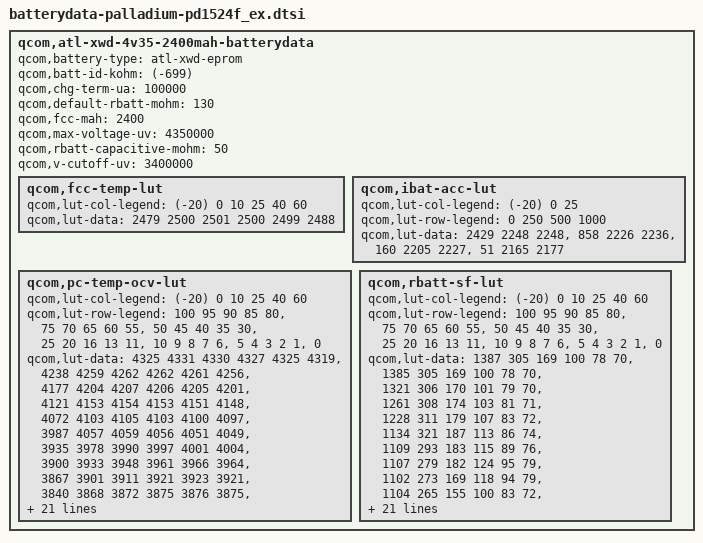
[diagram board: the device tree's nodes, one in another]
/* Copyright (c) 2013-2014, The Linux Foundation. All rights reserved.
 *
 * This program is free software; you can redistribute it and/or modify
 * it under the terms of the GNU General Public License version 2 and
 * only version 2 as published by the Free Software Foundation.
 *
 * This program is distributed in the hope that it will be useful,
 * but WITHOUT ANY WARRANTY; without even the implied warranty of
 * MERCHANTABILITY or FITNESS FOR A PARTICULAR PURPOSE.  See the
 * GNU General Public License for more details.
 */
qcom,atl-xwd-4v35-2400mah-batterydata {
	qcom,battery-type = "atl-xwd-eprom";
	qcom,batt-id-kohm = <(-699)>;
	qcom,chg-term-ua = <100000>;
	qcom,default-rbatt-mohm = <130>;
	qcom,fcc-mah = <2400>;
	qcom,max-voltage-uv = <4350000>;
	qcom,rbatt-capacitive-mohm = <50>;
	qcom,v-cutoff-uv = <3400000>;

	qcom,fcc-temp-lut {
		qcom,lut-col-legend = <(-20) 0 10 25 40 60>;
		qcom,lut-data = <2479 2500 2501 2500 2499 2488>;
	};

	qcom,ibat-acc-lut {
		qcom,lut-col-legend = <(-20) 0 25>;
		qcom,lut-row-legend = <0 250 500 1000>;
		qcom,lut-data = <2429 2248 2248>,
				<858 2226 2236>,
				<160 2205 2227>,
				<51 2165 2177>;
	};

	qcom,pc-temp-ocv-lut {
		qcom,lut-col-legend = <(-20) 0 10 25 40 60>;
		qcom,lut-row-legend = <100 95 90 85 80>,
					<75 70 65 60 55>,
					<50 45 40 35 30>,
					<25 20 16 13 11>,
					<10 9 8 7 6>,
					<5 4 3 2 1>,
					<0>;
		qcom,lut-data = <4325 4331 4330 4327 4325 4319>,
				<4238 4259 4262 4262 4261 4256>,
				<4177 4204 4207 4206 4205 4201>,
				<4121 4153 4154 4153 4151 4148>,
				<4072 4103 4105 4103 4100 4097>,
				<3987 4057 4059 4056 4051 4049>,
				<3935 3978 3990 3997 4001 4004>,
				<3900 3933 3948 3961 3966 3964>,
				<3867 3901 3911 3921 3923 3921>,
				<3840 3868 3872 3875 3876 3875>,
				<3820 3840 3843 3845 3845 3844>,
				<3804 3817 3821 3822 3822 3821>,
				<3790 3799 3802 3803 3803 3802>,
				<3777 3785 3787 3788 3788 3786>,
				<3764 3774 3775 3773 3769 3762>,
				<3750 3762 3762 3756 3748 3735>,
				<3733 3745 3746 3738 3729 3715>,
				<3717 3727 3725 3718 3708 3695>,
				<3704 3712 3707 3698 3688 3675>,
				<3692 3704 3700 3692 3683 3671>,
				<3684 3701 3698 3690 3682 3670>,
				<3674 3698 3695 3689 3680 3668>,
				<3661 3693 3693 3687 3678 3665>,
				<3647 3686 3688 3682 3673 3657>,
				<3626 3670 3674 3667 3655 3635>,
				<3593 3639 3641 3631 3618 3597>,
				<3551 3592 3595 3582 3568 3546>,
				<3492 3531 3535 3521 3505 3481>,
				<3405 3448 3439 3439 3422 3392>,
				<3258 3288 3291 3284 3298 3257>,
				<3000 3000 3000 3000 3000 3000>;
	};

	qcom,rbatt-sf-lut {
		qcom,lut-col-legend = <(-20) 0 10 25 40 60>;
		qcom,lut-row-legend = <100 95 90 85 80>,
					<75 70 65 60 55>,
					<50 45 40 35 30>,
					<25 20 16 13 11>,
					<10 9 8 7 6>,
					<5 4 3 2 1>,
					<0>;
		qcom,lut-data = <1387 305 169 100 78 70>,
				<1385 305 169 100 78 70>,
				<1321 306 170 101 79 70>,
				<1261 308 174 103 81 71>,
				<1228 311 179 107 83 72>,
				<1134 321 187 113 86 74>,
				<1109 293 183 115 89 76>,
				<1107 279 182 124 95 79>,
				<1102 273 169 118 94 79>,
				<1104 265 155 100 83 72>,
				<1120 264 153 96 78 70>,
				<1141 265 155 97 79 71>,
				<1170 269 158 100 82 73>,
				<1214 277 160 102 85 76>,
				<1267 288 163 102 83 73>,
				<1343 300 167 100 79 70>,
				<1433 311 169 100 80 71>,
				<1494 323 170 100 80 71>,
				<1408 319 169 98 78 69>,
				<1450 332 172 99 79 71>,
				<1486 341 175 101 81 72>,
				<1560 352 179 103 83 73>,
				<1680 364 185 106 85 75>,
				<1825 382 191 110 86 75>,
				<1980 393 197 107 83 73>,
				<2226 402 195 106 82 72>,
				<2536 417 200 107 83 73>,
				<2975 447 211 109 86 75>,
				<3726 483 227 115 89 81>,
				<7452 967 455 230 107 114>,
				<10571 1933 910 460 214 228>;
	};
};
